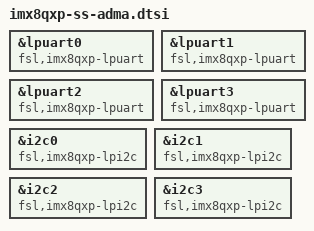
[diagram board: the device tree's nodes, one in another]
&lpuart0 {
	compatible = "fsl,imx8qxp-lpuart";
};
&lpuart1 {
	compatible = "fsl,imx8qxp-lpuart";
};
&lpuart2 {
	compatible = "fsl,imx8qxp-lpuart";
};
&lpuart3 {
	compatible = "fsl,imx8qxp-lpuart";
};
&i2c0 {
	compatible = "fsl,imx8qxp-lpi2c", "fsl,imx7ulp-lpi2c";
};
&i2c1 {
	compatible = "fsl,imx8qxp-lpi2c", "fsl,imx7ulp-lpi2c";
};
&i2c2 {
	compatible = "fsl,imx8qxp-lpi2c", "fsl,imx7ulp-lpi2c";
};
&i2c3 {
	compatible = "fsl,imx8qxp-lpi2c", "fsl,imx7ulp-lpi2c";
};
